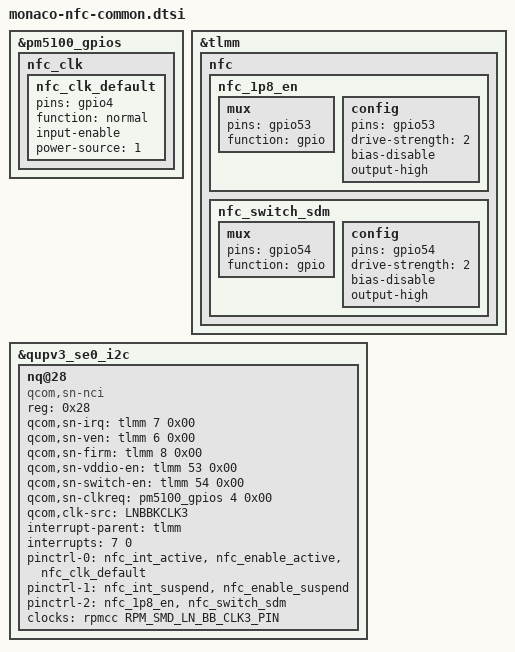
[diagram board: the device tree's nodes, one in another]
#include <dt-bindings/clock/qcom,rpmcc.h>

&pm5100_gpios {
	nfc_clk {
		nfc_clk_default: nfc_clk_default {
		pins = "gpio4";
		function = "normal";
		input-enable;
		power-source = <1>;
		};
	};
};

&tlmm {
	nfc {
		nfc_1p8_en: nfc_1p8_en {
			mux {
				pins = "gpio53";
				function = "gpio";
			};

			config {
				pins = "gpio53";
				drive-strength = <2>; /* 2 MA */
				bias-disable;
				output-high;
			};
		};

		nfc_switch_sdm: nfc_switch_sdm {
			mux {
				pins = "gpio54";
				function = "gpio";
			};

			config {
				pins = "gpio54";
				drive-strength = <2>; /* 2 MA */
				bias-disable;
				output-high;
			};
		};
	};
};

&qupv3_se0_i2c {
	status = "ok";
	#address-cells = <1>;
	#size-cells = <0>;
	nq@28 {
		compatible = "qcom,sn-nci";
		reg = <0x28>;
		qcom,sn-irq = <&tlmm 7 0x00>;
		qcom,sn-ven = <&tlmm 6 0x00>;
		qcom,sn-firm = <&tlmm 8 0x00>;
		qcom,sn-vddio-en = <&tlmm 53 0x00>;
		qcom,sn-switch-en = <&tlmm 54 0x00>;
		qcom,sn-clkreq = <&pm5100_gpios 4 0x00>;
		qcom,clk-src = "LNBBKCLK3";
		interrupt-parent = <&tlmm>;
		interrupts = <7 0>;
		interrupt-names = "nfc_irq";
		pinctrl-names = "nfc_active", "nfc_suspend", "default";
		pinctrl-0 = <&nfc_int_active &nfc_enable_active &nfc_clk_default>;
		pinctrl-1 = <&nfc_int_suspend &nfc_enable_suspend>;
		pinctrl-2 = <&nfc_1p8_en &nfc_switch_sdm>;
		clocks = <&rpmcc RPM_SMD_LN_BB_CLK3_PIN>;
		clock-names = "nfc_ref_clk";
	};
};

